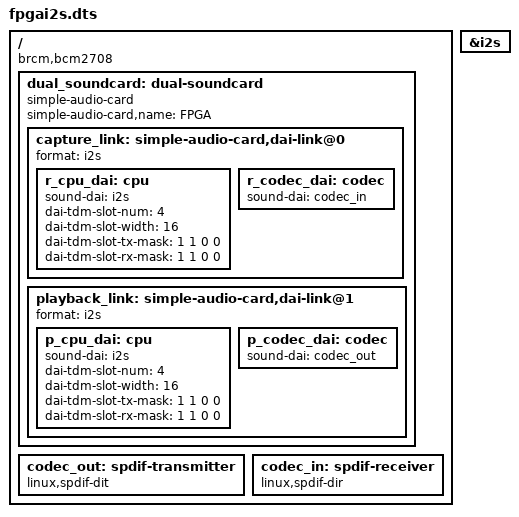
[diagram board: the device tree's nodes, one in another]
/dts-v1/;
/plugin/;

/ {
    compatible = "brcm,bcm2708";

    fragment@0 {
        target-path = "/";
        __overlay__ {
            dual_soundcard: dual-soundcard {
                compatible = "simple-audio-card";
                simple-audio-card,name = "FPGA";

                status="okay";

                capture_link: simple-audio-card,dai-link@0 {
                    format = "i2s";

                    r_cpu_dai: cpu {
                        sound-dai = <&i2s>;
                        dai-tdm-slot-num = <4>;
                        dai-tdm-slot-width = <16>;
                        dai-tdm-slot-tx-mask = <1 1 0 0>;
                        dai-tdm-slot-rx-mask = <1 1 0 0>;
                    };

                    r_codec_dai: codec {
                        sound-dai = <&codec_in>;
                    };
                };

                playback_link: simple-audio-card,dai-link@1 {
                    format = "i2s";

                    p_cpu_dai: cpu {
                        sound-dai = <&i2s>;
                        dai-tdm-slot-num = <4>;
                        dai-tdm-slot-width = <16>;
                        dai-tdm-slot-tx-mask = <1 1 0 0>;
                        dai-tdm-slot-rx-mask = <1 1 0 0>;
                    };

                    p_codec_dai: codec {
                        sound-dai = <&codec_out>;
                    };
                };

            };
        };
        };

    fragment@1 {
        target-path = "/";
        __overlay__ {
            codec_out: spdif-transmitter {
                #address-cells = <0>;
                #size-cells = <0>;
                #sound-dai-cells = <0>;
                compatible = "linux,spdif-dit";
                status = "okay";
            };
            codec_in: spdif-receiver {
                #address-cells = <0>;
                #size-cells = <0>;
                #sound-dai-cells = <0>;
                compatible = "linux,spdif-dir";
                status = "okay";
            };
        };
    };

    fragment@2 {
        target = <&i2s>;
        __overlay__ {
            #sound-dai-cells = <0>;
            status = "okay";
            };
    };

};

